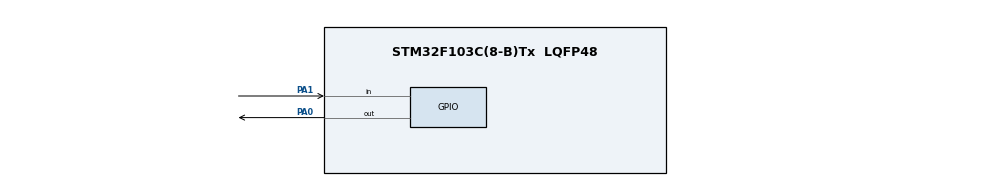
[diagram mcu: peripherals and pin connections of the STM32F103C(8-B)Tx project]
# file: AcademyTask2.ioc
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Mcu.Family=STM32F1
Mcu.Name=STM32F103C(8-B)Tx
Mcu.Package=LQFP48
NVIC.PriorityGroup=NVIC_PRIORITYGROUP_4
PA0-WKUP.Signal=GPIO_Output
PA1.GPIO_PuPd=GPIO_PULLUP
PA1.Signal=GPIO_Input
PA13.Mode=Serial_Wire
PA13.Signal=SYS_JTMS-SWDIO
PA14.Mode=Serial_Wire
PA14.Signal=SYS_JTCK-SWCLK
ProjectManager.HeapSize=0x200
ProjectManager.StackSize=0x400
ProjectManager.TargetToolchain=STM32CubeIDE
RCC.APB1Freq_Value=8000000
RCC.APB2Freq_Value=8000000
board=custom

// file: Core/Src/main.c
/* USER CODE BEGIN Header */
/**
  ******************************************************************************
  * @file           : main.c
  * @brief          : Main program body
  ******************************************************************************
  * @attention
  *
  * Copyright (c) 2025 STMicroelectronics.
  * All rights reserved.
  *
  * This software is licensed under terms that can be found in the LICENSE file
  * in the root directory of this software component.
  * If no LICENSE file comes with this software, it is provided AS-IS.
  *
  ******************************************************************************
  */
/* USER CODE END Header */
#include "main.h"
#include "gpio.h"

void SystemClock_Config(void);

int main(void)
{

  /* MCU Configuration--------------------------------------------------------*/

  /* Reset of all peripherals, Initializes the Flash interface and the Systick. */
  HAL_Init();

  /* Configure the system clock */
  SystemClock_Config();

  /* Initialize all configured peripherals */
  MX_GPIO_Init();
  /* USER CODE BEGIN 2 */
  uint8_t counter = 0;
   uint8_t button_state = 1;
   uint8_t last_state = 1;
 uint8_t Debounce_Threshold = 5;
  /* USER CODE END 2 */

  /* Infinite loop */
  while (1)
  {
	     uint8_t current = HAL_GPIO_ReadPin(GPIOA, GPIO_PIN_0); //Page 249

	     if (current == last_state)
	     {
	       if (counter < Debounce_Threshold)
	         counter++;
	       else if (counter == Debounce_Threshold)
	       {
	         if (current != button_state)
	         {
	           button_state = current;
	           if (button_state == GPIO_PIN_RESET)
	           {
	             HAL_GPIO_TogglePin(GPIOC, GPIO_PIN_13); //Page 252
	           }
	         }
	       }
	     }
	     else
	     {
	       counter = 0;
	     }

	     last_state = current;
	     HAL_Delay(1);
	   }
}

void SystemClock_Config(void)
{
  RCC_OscInitTypeDef RCC_OscInitStruct = {0};
  RCC_ClkInitTypeDef RCC_ClkInitStruct = {0};

  /** Initializes the RCC Oscillators according to the specified parameters
  * in the RCC_OscInitTypeDef structure.
  */
  RCC_OscInitStruct.OscillatorType = RCC_OSCILLATORTYPE_HSI;
  RCC_OscInitStruct.HSIState = RCC_HSI_ON;
  RCC_OscInitStruct.HSICalibrationValue = RCC_HSICALIBRATION_DEFAULT;
  RCC_OscInitStruct.PLL.PLLState = RCC_PLL_NONE;
  if (HAL_RCC_OscConfig(&RCC_OscInitStruct) != HAL_OK)
  {
    Error_Handler();
  }

  /** Initializes the CPU, AHB and APB buses clocks
  */
  RCC_ClkInitStruct.ClockType = RCC_CLOCKTYPE_HCLK|RCC_CLOCKTYPE_SYSCLK
                              |RCC_CLOCKTYPE_PCLK1|RCC_CLOCKTYPE_PCLK2;
  RCC_ClkInitStruct.SYSCLKSource = RCC_SYSCLKSOURCE_HSI;
  RCC_ClkInitStruct.AHBCLKDivider = RCC_SYSCLK_DIV1;
  RCC_ClkInitStruct.APB1CLKDivider = RCC_HCLK_DIV1;
  RCC_ClkInitStruct.APB2CLKDivider = RCC_HCLK_DIV1;

  if (HAL_RCC_ClockConfig(&RCC_ClkInitStruct, FLASH_LATENCY_0) != HAL_OK)
  {
    Error_Handler();
  }
}

void Error_Handler(void)
{
  __disable_irq();
  while (1)
  {
  }
}
